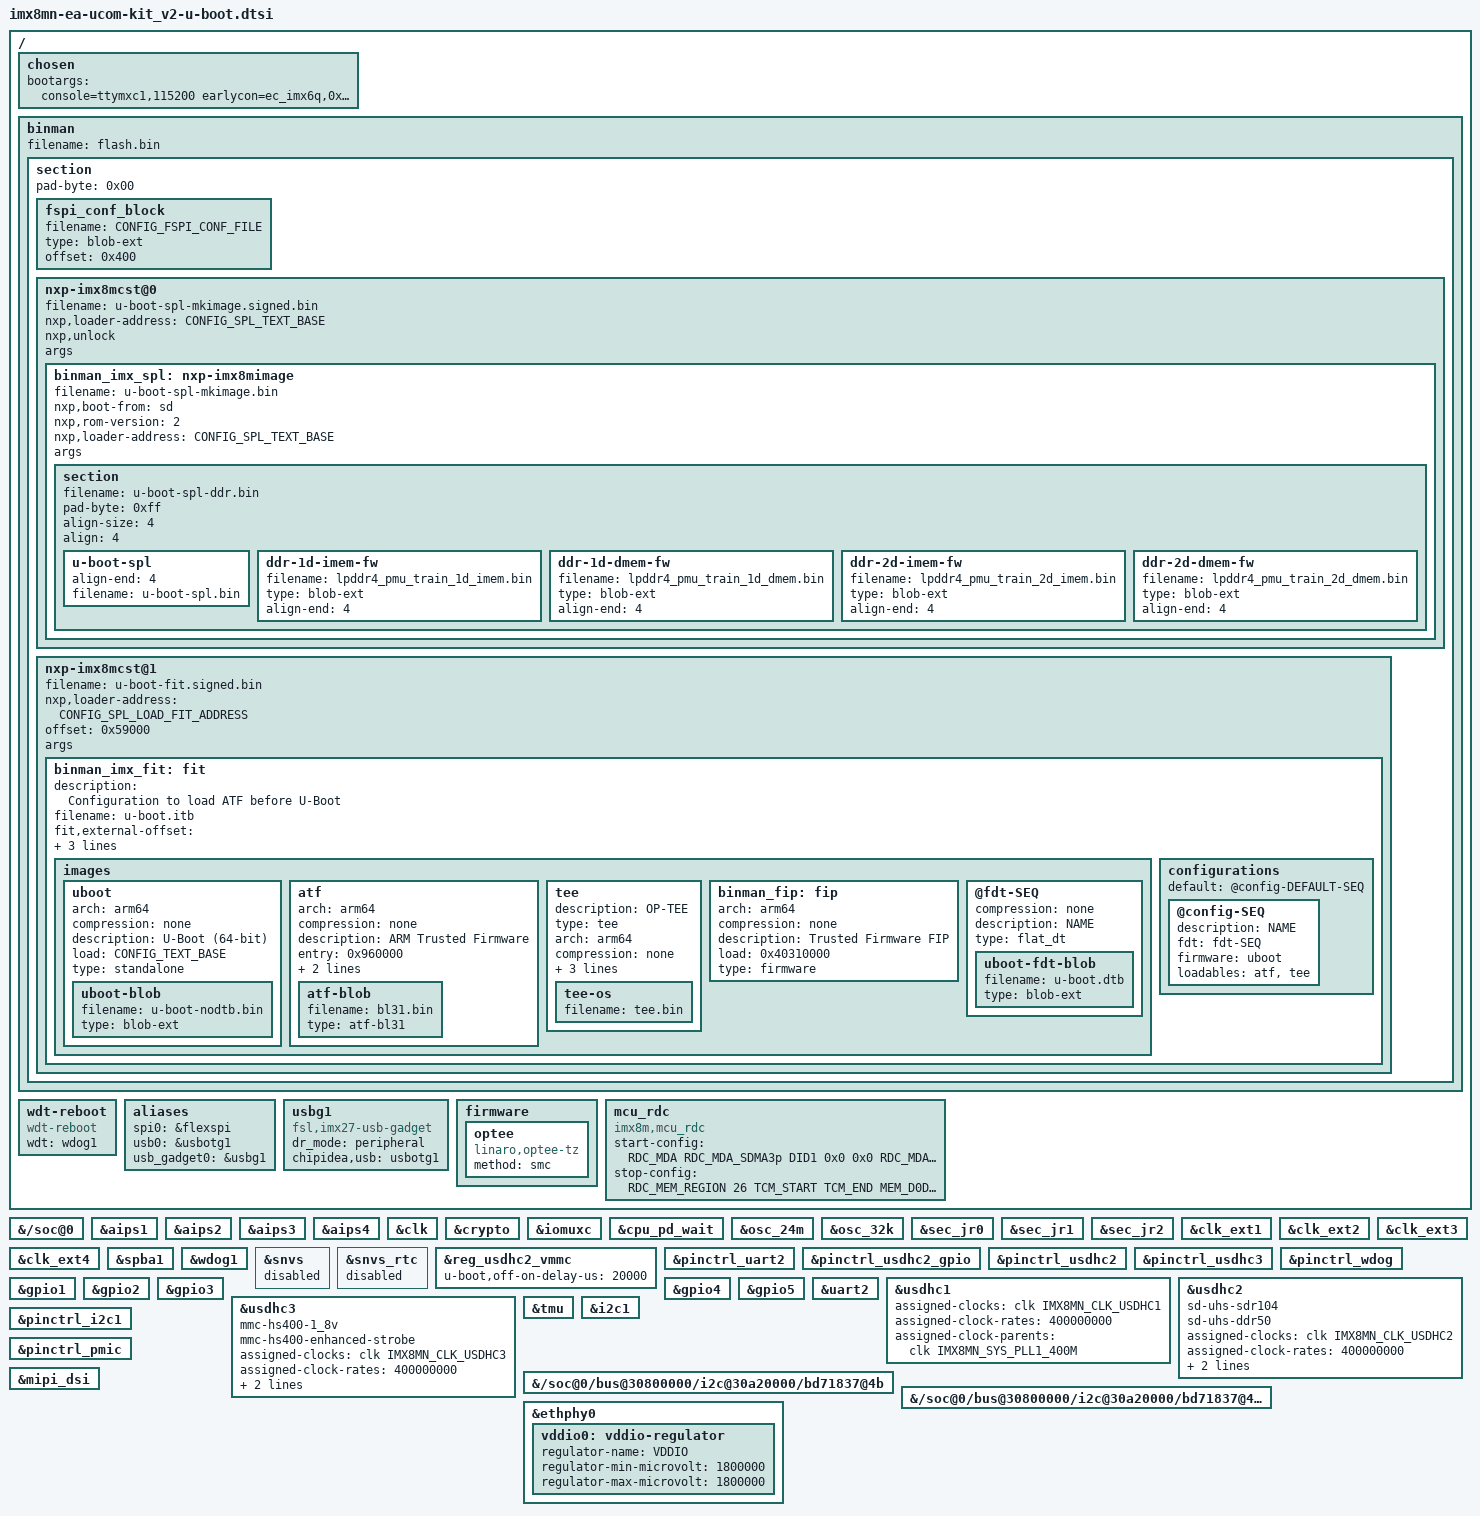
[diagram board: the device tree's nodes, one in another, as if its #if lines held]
// SPDX-License-Identifier: GPL-2.0+
/*
 * Copyright 2019 NXP
 */

#include "imx8mn-sec-def.h"

/ {
	chosen {
		bootargs = "console=ttymxc1,115200 earlycon=ec_imx6q,0x30890000,115200";
	};

	binman: binman {
	};

	wdt-reboot {
		compatible = "wdt-reboot";
		wdt = <&wdog1>;
		bootph-pre-ram;
	};

	aliases {
		spi0 = &flexspi;
		usb0 = &usbotg1;
		usb_gadget0 = &usbg1;
	};

	usbg1: usbg1 {
		compatible = "fsl,imx27-usb-gadget";
		dr_mode = "peripheral";
		chipidea,usb = <&usbotg1>;
		status = "okay";
	};

#ifdef CONFIG_OPTEE
	firmware {
		optee {
			compatible = "linaro,optee-tz";
			method = "smc";
		};
	};
#endif

	mcu_rdc {
		compatible = "imx8m,mcu_rdc";
			    /* rdc config when MCU starts
			     * master
			     *   SDMA3p --> domain 1
			     *   SDMA3b --> domian 1
			     *   SDMA3_SPBA2  --> domian 1
			     * peripheral:
			     *   SAI3   --> Only Domian 1 can access
			     *   UART4  --> Only Domian 1 can access
			     *   GPT1   --> Only Domian 1 can access
			     * memory:
			     *   TCM    --> Only Domian 1 can access (0x7E0000~0x81FFFF)
			     *   DDR    --> Only Domian 1 can access (0x80000000~0x81000000)
			     * end.
			     */
		start-config = <
			    RDC_MDA  RDC_MDA_SDMA3p DID1 0x0 0x0
			    RDC_MDA  RDC_MDA_SDMA3b DID1 0x0 0x0
			    RDC_MDA  RDC_MDA_SDMA3_SPBA2 DID1 0x0 0x0
			    RDC_PDAP RDC_PDAP_SAI3  PDAP_D1_ACCESS 0x0 0x0
			    RDC_PDAP RDC_PDAP_UART4 PDAP_D1_ACCESS 0x0 0x0
			    RDC_PDAP RDC_PDAP_GPT1  PDAP_D1_ACCESS 0x0 0x0
			    RDC_MEM_REGION 26 TCM_START TCM_END MEM_D1_ACCESS
			    RDC_MEM_REGION 0 M4_EVK_DDR4_START M4_EVK_DDR4_END MEM_D1_ACCESS
			    0x0      0x0            0x0  0x0 0x0
			  >;
			    /* rdc config when MCU stops
			     * memory:
			     *   TCM    --> domain 0/1 can access (0x7E0000~0x81FFFF)
			     *   DDR    --> domain 0/1 can access (0x80000000~0x81000000)
			     * end.
			     */
		stop-config = <
			    RDC_MEM_REGION 26 TCM_START TCM_END MEM_D0D1_ACCESS
			    RDC_MEM_REGION 0 M4_EVK_DDR4_START M4_EVK_DDR4_END MEM_D0D1_ACCESS
			    0x0      0x0            0x0  0x0 0x0
			  >;
	};

};

&{/soc@0} {
	bootph-all;
	bootph-pre-ram;
};

&aips1 {
	bootph-pre-ram;
	bootph-all;
};

&aips2 {
	bootph-pre-ram;
};

&aips3 {
	bootph-pre-ram;
};

&aips4 {
	bootph-pre-ram;
};

&clk {
	bootph-pre-ram;
	bootph-all;
	/delete-property/ assigned-clocks;
	/delete-property/ assigned-clock-parents;
	/delete-property/ assigned-clock-rates;
};

#ifdef CONFIG_FSL_CAAM
&crypto {
	bootph-pre-ram;
};
#endif

&iomuxc {
	bootph-pre-ram;
};

&cpu_pd_wait {
	/delete-property/ compatible;
};

&osc_24m {
	bootph-pre-ram;
	bootph-all;
};

&osc_32k {
	bootph-pre-ram;
	bootph-all;
};

#ifdef CONFIG_FSL_CAAM
&sec_jr0 {
	bootph-pre-ram;
};

&sec_jr1 {
	bootph-pre-ram;
};

&sec_jr2 {
	bootph-pre-ram;
};
#endif

&clk_ext1 {
	bootph-pre-ram;
	bootph-all;
};

&clk_ext2 {
	bootph-pre-ram;
	bootph-all;
};

&clk_ext3 {
	bootph-pre-ram;
	bootph-all;
};

&clk_ext4 {
	bootph-pre-ram;
	bootph-all;
};

&spba1 {
	bootph-pre-ram;
};

&wdog1 {
	bootph-pre-ram;
};

&snvs {
	status = "disabled";
};

&snvs_rtc {
	status = "disabled";
};

&binman {
	filename = "flash.bin";
	section {
		pad-byte = <0x00>;

#ifdef CONFIG_FSPI_CONF_HEADER
		fspi_conf_block {
			filename = CONFIG_FSPI_CONF_FILE;
			type = "blob-ext";
			offset = <0x400>;
		};
#endif

#ifdef CONFIG_IMX_HAB
		nxp-imx8mcst@0 {
			filename = "u-boot-spl-mkimage.signed.bin";
			nxp,loader-address = <CONFIG_SPL_TEXT_BASE>;
			nxp,unlock;
			args;	/* Needed by mkimage etype superclass */
#endif

			binman_imx_spl: nxp-imx8mimage {
				filename = "u-boot-spl-mkimage.bin";
				nxp,boot-from = "sd";
				nxp,rom-version = <2>;
				nxp,loader-address = <CONFIG_SPL_TEXT_BASE>;
				args;	/* Needed by mkimage etype superclass */

				section {
					filename = "u-boot-spl-ddr.bin";
					pad-byte = <0xff>;
					align-size = <4>;
					align = <4>;

					u-boot-spl {
						align-end = <4>;
						filename = "u-boot-spl.bin";
					};

					ddr-1d-imem-fw {
#ifdef CONFIG_IMX8M_LPDDR4
						filename = "lpddr4_pmu_train_1d_imem.bin";
#elif CONFIG_IMX8M_DDR4
						filename = "ddr4_imem_1d_201810.bin";
#else
						filename = "ddr3_imem_1d.bin";
#endif
						type = "blob-ext";
						align-end = <4>;
					};

					ddr-1d-dmem-fw {
#ifdef CONFIG_IMX8M_LPDDR4
						filename = "lpddr4_pmu_train_1d_dmem.bin";
#elif CONFIG_IMX8M_DDR4
						filename = "ddr4_dmem_1d_201810.bin";
#else
						filename = "ddr3_dmem_1d.bin";
#endif
						type = "blob-ext";
						align-end = <4>;
					};

#if defined(CONFIG_IMX8M_LPDDR4) || defined(CONFIG_IMX8M_DDR4)
					ddr-2d-imem-fw {
#ifdef CONFIG_IMX8M_LPDDR4
						filename = "lpddr4_pmu_train_2d_imem.bin";
#else
						filename = "ddr4_imem_2d_201810.bin";
#endif
						type = "blob-ext";
						align-end = <4>;
					};

					ddr-2d-dmem-fw {
#ifdef CONFIG_IMX8M_LPDDR4
						filename = "lpddr4_pmu_train_2d_dmem.bin";
#else
						filename = "ddr4_dmem_2d_201810.bin";
#endif
						type = "blob-ext";
						align-end = <4>;
					};
#endif
				};
			};

#ifdef CONFIG_IMX_HAB
		};

		nxp-imx8mcst@1 {
			filename = "u-boot-fit.signed.bin";
			nxp,loader-address = <CONFIG_SPL_LOAD_FIT_ADDRESS>;
#ifdef CONFIG_FSPI_CONF_HEADER
			offset = <0x59000>;
#else
			offset = <0x58000>;
#endif
			args;	/* Needed by mkimage etype superclass */
#endif

			binman_imx_fit: fit {
				description = "Configuration to load ATF before U-Boot";
				filename = "u-boot.itb";
#ifndef CONFIG_IMX_HAB
				fit,external-offset = <CONFIG_FIT_EXTERNAL_OFFSET>;
#endif
				fit,fdt-list = "of-list";
				#address-cells = <1>;
#ifdef CONFIG_FSPI_CONF_HEADER
				offset = <0x59000>;
#else
				offset = <0x58000>;
#endif

				images {
					uboot {
						arch = "arm64";
						compression = "none";
						description = "U-Boot (64-bit)";
						load = <CONFIG_TEXT_BASE>;
						type = "standalone";

						uboot-blob {
							filename = "u-boot-nodtb.bin";
							type = "blob-ext";
						};
					};

#ifndef CONFIG_ARMV8_PSCI
					atf {
						arch = "arm64";
						compression = "none";
						description = "ARM Trusted Firmware";
						entry = <0x960000>;
						load = <0x960000>;
						type = "firmware";

						atf-blob {
							filename = "bl31.bin";
							type = "atf-bl31";
						};
					};
#endif

#ifdef CONFIG_OPTEE
					tee: tee {
						description = "OP-TEE";
						type = "tee";
						arch = "arm64";
						compression = "none";
						os = "tee";
						load = <CONFIG_IMX8M_OPTEE_LOAD_ADDR>;
						entry = <CONFIG_IMX8M_OPTEE_LOAD_ADDR>;

						tee-os {
							filename = "tee.bin";
						};
					};
#endif

					binman_fip: fip {
						arch = "arm64";
						compression = "none";
						description = "Trusted Firmware FIP";
						load = <0x40310000>;
						type = "firmware";
					};

					@fdt-SEQ {
						compression = "none";
						description = "NAME";
						type = "flat_dt";

						uboot-fdt-blob {
							filename = "u-boot.dtb";
							type = "blob-ext";
						};
					};
				};

				configurations {
					default = "@config-DEFAULT-SEQ";

					@config-SEQ {
						description = "NAME";
						fdt = "fdt-SEQ";
						firmware = "uboot";
#ifndef CONFIG_ARMV8_PSCI
#ifdef CONFIG_OPTEE
						loadables = "atf", "tee";
#else
						loadables = "atf";
#endif
#endif
					};
				};
			};
#ifdef CONFIG_IMX_HAB
		};
#endif
	};
};


&reg_usdhc2_vmmc {
	bootph-pre-ram;
	u-boot,off-on-delay-us = <20000>;
};

&pinctrl_uart2 {
	bootph-pre-ram;
};

&pinctrl_usdhc2_gpio {
	bootph-pre-ram;
};

&pinctrl_usdhc2 {
	bootph-pre-ram;
};

&pinctrl_usdhc3 {
	bootph-pre-ram;
};

&pinctrl_wdog {
	bootph-pre-ram;
};

&gpio1 {
	bootph-pre-ram;
};

&gpio2 {
	bootph-pre-ram;
};

&gpio3 {
	bootph-pre-ram;
};

&gpio4 {
	bootph-pre-ram;
};

&gpio5 {
	bootph-pre-ram;
};

&uart2 {
	bootph-pre-ram;
};

&usdhc1 {
	bootph-pre-ram;
	assigned-clocks = <&clk IMX8MN_CLK_USDHC1>;
	assigned-clock-rates = <400000000>;
	assigned-clock-parents = <&clk IMX8MN_SYS_PLL1_400M>;
};

&usdhc2 {
	bootph-pre-ram;
	sd-uhs-sdr104;
	sd-uhs-ddr50;
	assigned-clocks = <&clk IMX8MN_CLK_USDHC2>;
	assigned-clock-rates = <400000000>;
	assigned-clock-parents = <&clk IMX8MN_SYS_PLL1_400M>;
};

&usdhc3 {
	bootph-pre-ram;
	mmc-hs400-1_8v;
	mmc-hs400-enhanced-strobe;
	assigned-clocks = <&clk IMX8MN_CLK_USDHC3>;
	assigned-clock-rates = <400000000>;
	assigned-clock-parents = <&clk IMX8MN_SYS_PLL1_400M>;
};

&tmu {
	bootph-all;
};

&i2c1 {
	bootph-pre-ram;
};

&{/soc@0/bus@30800000/i2c@30a20000/bd71837@4b} {
	bootph-pre-ram;
};

&{/soc@0/bus@30800000/i2c@30a20000/bd71837@4b/regulators} {
	bootph-pre-ram;
};

&pinctrl_i2c1 {
	bootph-pre-ram;
};

&pinctrl_pmic {
	bootph-pre-ram;
};

&ethphy0 {
	vddio0: vddio-regulator {
		regulator-name = "VDDIO";
		regulator-min-microvolt = <1800000>;
		regulator-max-microvolt = <1800000>;
	};
};

&mipi_dsi {
	/delete-property/ assigned-clocks;
	/delete-property/ assigned-clock-parents;
	/delete-property/ assigned-clock-rates;
};
